# MKV31F12810 register map
Vendor: Freescale Semiconductor, Inc.; Series: Kinetis_V; File version: 1.6
CPU: CM4 r0p1, little endian, no MPU, FPU, VTOR, 4 interrupt priority bits
Registers are 32-bit, read-write, reset 0x0 unless marked. A register's access mark holds for its fields unless they carry their own. Offsets are from the block's base; [hi:lo] are bit positions; {n}, {i} and the like mark numbered series; 'fields as' and 'values as' point back to an identical list.

## LPTMR0 — Low Power Timer
Base 0x40040000; register names take the prefix LPTMR0_
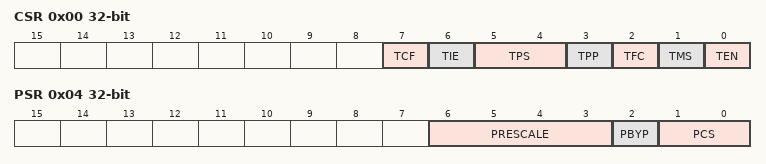
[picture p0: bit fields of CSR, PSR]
0x00 CSR — Low Power Timer Control Status Register
  [7] TCF — Timer Compare Flag
    0=The value of CNR is not equal to CMR and increments; 1=The value of CNR is equal to CMR and increments
  [6] TIE — Timer Interrupt Enable
    0=Timer interrupt disabled; 1=Timer interrupt enabled
  [5:4] TPS — Timer Pin Select
    {v}=Pulse counter input {v} is selected (v=0..3)
  [3] TPP — Timer Pin Polarity
    0=Pulse Counter input source is active-high, and the CNR will increment on the rising-edge; 1=Pulse Counter input source is active-low, and the CNR will increment on the falling-edge
  [2] TFC — Timer Free-Running Counter
    0=CNR is reset whenever TCF is set; 1=CNR is reset on overflow
  [1] TMS — Timer Mode Select
    0=Time Counter mode; 1=Pulse Counter mode
  [0] TEN — Timer Enable
    0=LPTMR is disabled and internal logic is reset; 1=LPTMR is enabled
0x04 PSR — Low Power Timer Prescale Register
  [6:3] PRESCALE — Prescale Value
    0=Prescaler divides the prescaler clock by 2; glitch filter does not support this configuration; 1=Prescaler divides the prescaler clock by 4; glitch filter recognizes change on input pin after 2 rising clock edges; 2=Prescaler divides the prescaler clock by 8; glitch filter recognizes change on input pin after 4 rising clock edges; 3=Prescaler divides the prescaler clock by 16; glitch filter recognizes change on input pin after 8 rising clock edges; 4=Prescaler divides the prescaler clock by 32; glitch filter recognizes change on input pin after 16 rising clock edges; 5=Prescaler divides the prescaler clock by 64; glitch filter recognizes change on input pin after 32 rising clock edges; 6=Prescaler divides the prescaler clock by 128; glitch filter recognizes change on input pin after 64 rising clock edges; 7=Prescaler divides the prescaler clock by 256; glitch filter recognizes change on input pin after 128 rising clock edges; 8=Prescaler divides the prescaler clock by 512; glitch filter recognizes change on input pin after 256 rising clock edges; 9=Prescaler divides the prescaler clock by 1024; glitch filter recognizes change on input pin after 512 rising clock edges; 10=Prescaler divides the prescaler clock by 2048; glitch filter recognizes change on input pin after 1024 rising clock edges; 11=Prescaler divides the prescaler clock by 4096; glitch filter recognizes change on input pin after 2048 rising clock edges; 12=Prescaler divides the prescaler clock by 8192; glitch filter recognizes change on input pin after 4096 rising clock edges; 13=Prescaler divides the prescaler clock by 16,384; glitch filter recognizes change on input pin after 8192 rising clock edges; 14=Prescaler divides the prescaler clock by 32,768; glitch filter recognizes change on input pin after 16,384 rising clock edges; 15=Prescaler divides the prescaler clock by 65,536; glitch filter recognizes change on input pin after 32,768 rising clock edges
  [2] PBYP — Prescaler Bypass
    0=Prescaler/glitch filter is enabled; 1=Prescaler/glitch filter is bypassed
  [1:0] PCS — Prescaler Clock Select
    {v}=Prescaler/glitch filter clock {v} selected (v=0..3)
0x08 CMR — Low Power Timer Compare Register
  [15:0] COMPARE — Compare Value
0x0C CNR — Low Power Timer Counter Register
  [15:0] COUNTER — Counter Value

## RFSYS — System register file
Base 0x40041000; register names take the prefix RFSYS_
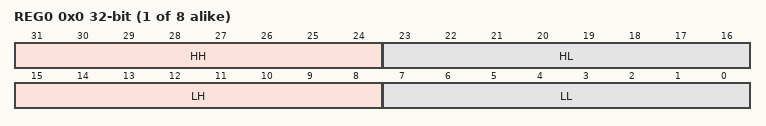
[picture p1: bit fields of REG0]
{0x0+4i} REG{i} (i=0..7) — Register file register
  [31:24] HH, [23:16] HL, [15:8] LH, [7:0] LL

## PORTA — Pin Control and Interrupts
Base 0x40049000; register names take the prefix PORTA_
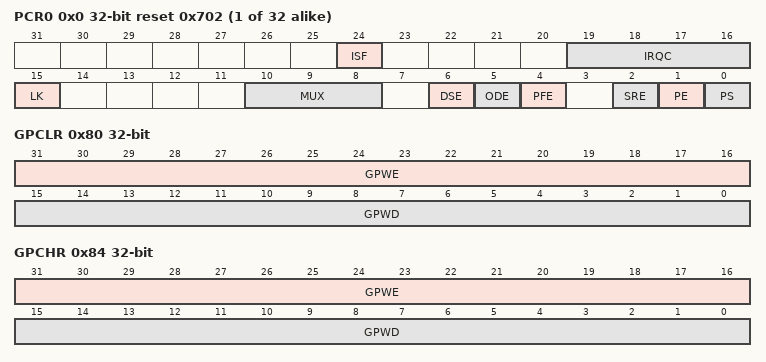
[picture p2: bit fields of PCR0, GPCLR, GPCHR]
{0x0+4i} PCR{i} (i=0..31) reset 0x702 — Pin Control Register n
  [24] ISF — Interrupt Status Flag
    0=Configured interrupt is not detected; 1=Configured interrupt is detected. If the pin is configured to generate a DMA request, then the corresponding flag will be cleared automatically at the completion of the requested DMA transfer. Otherwise, the flag remains set until a logic 1 is written to the flag. If the pin is configured for a level sensitive interrupt and the pin remains asserted, then the flag is set again immediately after it is cleared.
  [19:16] IRQC — Interrupt Configuration
    0=Interrupt/DMA request disabled; 1=DMA request on rising edge; 2=DMA request on falling edge; 3=DMA request on either edge; 8=Interrupt when logic 0; 9=Interrupt on rising-edge; 10=Interrupt on falling-edge; 11=Interrupt on either edge; 12=Interrupt when logic 1
  [15] LK — Lock Register
    0=Pin Control Register fields [15:0] are not locked; 1=Pin Control Register fields [15:0] are locked and cannot be updated until the next system reset
  [10:8] MUX — Pin Mux Control
    0=Pin disabled (analog); 1=Alternative 1 (GPIO); {v}=Alternative {v} (chip-specific) (v=2..7)
  [6] DSE — Drive Strength Enable
    0=Low drive strength is configured on the corresponding pin, if pin is configured as a digital output; 1=High drive strength is configured on the corresponding pin, if pin is configured as a digital output
  [5] ODE — Open Drain Enable
    0=Open drain output is disabled on the corresponding pin; 1=Open drain output is enabled on the corresponding pin, if the pin is configured as a digital output
  [4] PFE — Passive Filter Enable
    0=Passive input filter is disabled on the corresponding pin; 1=Passive input filter is enabled on the corresponding pin, if the pin is configured as a digital input. Refer to the device data sheet for filter characteristics.
  [2] SRE — Slew Rate Enable
    0=Fast slew rate is configured on the corresponding pin, if the pin is configured as a digital output; 1=Slow slew rate is configured on the corresponding pin, if the pin is configured as a digital output
  [1] PE — Pull Enable
    0=Internal pullup or pulldown resistor is not enabled on the corresponding pin; 1=Internal pullup or pulldown resistor is enabled on the corresponding pin, if the pin is configured as a digital input
  [0] PS — Pull Select
    0=Internal pulldown resistor is enabled on the corresponding pin, if the corresponding PE field is set; 1=Internal pullup resistor is enabled on the corresponding pin, if the corresponding PE field is set
0x80 GPCLR wo — Global Pin Control Low Register
  [31:16] GPWE — Global Pin Write Enable
    0=Corresponding Pin Control Register is not updated with the value in GPWD; 1=Corresponding Pin Control Register is updated with the value in GPWD
  [15:0] GPWD — Global Pin Write Data
0x84 GPCHR wo — Global Pin Control High Register
  fields as GPCLR
0xA0 ISFR — Interrupt Status Flag Register
  [31:0] ISF — Interrupt Status Flag
    values as PCR0.ISF

## Notices in the file
Redistribution and use in source and binary forms, with or without modification,
are permitted provided that the following conditions are met:
o Redistributions of source code must retain the above copyright notice, this list
of conditions and the following disclaimer.
o Redistributions in binary form must reproduce the above copyright notice, this
list of conditions and the following disclaimer in the documentation and/or
other materials provided with the distribution.
o Neither the name of Freescale Semiconductor, Inc. nor the names of its
contributors may be used to endorse or promote products derived from this
software without specific prior written permission.
THIS SOFTWARE IS PROVIDED BY THE COPYRIGHT HOLDERS AND CONTRIBUTORS "AS IS" AND
ANY EXPRESS OR IMPLIED WARRANTIES, INCLUDING, BUT NOT LIMITED TO, THE IMPLIED
WARRANTIES OF MERCHANTABILITY AND FITNESS FOR A PARTICULAR PURPOSE ARE
DISCLAIMED. IN NO EVENT SHALL THE COPYRIGHT HOLDER OR CONTRIBUTORS BE LIABLE FOR
ANY DIRECT, INDIRECT, INCIDENTAL, SPECIAL, EXEMPLARY, OR CONSEQUENTIAL DAMAGES
(INCLUDING, BUT NOT LIMITED TO, PROCUREMENT OF SUBSTITUTE GOODS OR SERVICES;
LOSS OF USE, DATA, OR PROFITS; OR BUSINESS INTERRUPTION) HOWEVER CAUSED AND ON
ANY THEORY OF LIABILITY, WHETHER IN CONTRACT, STRICT LIABILITY, OR TORT
(INCLUDING NEGLIGENCE OR OTHERWISE) ARISING IN ANY WAY OUT OF THE USE OF THIS
SOFTWARE, EVEN IF ADVISED OF THE POSSIBILITY OF SUCH DAMAGE.
